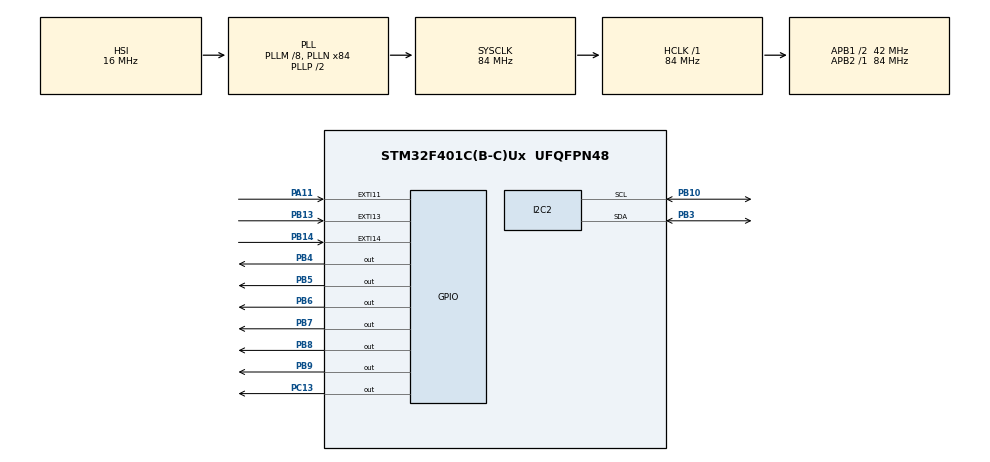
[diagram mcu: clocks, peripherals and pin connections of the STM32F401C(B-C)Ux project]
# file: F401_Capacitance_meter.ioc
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I2C2.I2C_Mode=I2C_Fast
Mcu.Family=STM32F4
Mcu.Name=STM32F401C(B-C)Ux
Mcu.Package=UFQFPN48
NVIC.EXTI15_10_IRQn=true\:0\:0\:false\:false\:true\:true\:true
NVIC.PriorityGroup=NVIC_PRIORITYGROUP_4
NVIC.TIM2_IRQn=true\:0\:0\:false\:false\:true\:true\:true
PA11.Signal=GPXTI11
PA13.Mode=Serial_Wire
PA13.Signal=SYS_JTMS-SWDIO
PA14.Mode=Serial_Wire
PA14.Signal=SYS_JTCK-SWCLK
PB10.Mode=I2C
PB10.Signal=I2C2_SCL
PB13.GPIO_PuPd=GPIO_PULLDOWN
PB13.Signal=GPXTI13
PB14.GPIO_PuPd=GPIO_PULLDOWN
PB14.Signal=GPXTI14
PB3.Mode=I2C
PB3.Signal=I2C2_SDA
PB4.PinState=GPIO_PIN_RESET
PB4.Signal=GPIO_Output
PB5.PinState=GPIO_PIN_SET
PB5.Signal=GPIO_Output
PB6.PinState=GPIO_PIN_SET
PB6.Signal=GPIO_Output
PB7.PinState=GPIO_PIN_SET
PB7.Signal=GPIO_Output
PB8.PinState=GPIO_PIN_SET
PB8.Signal=GPIO_Output
PB9.PinState=GPIO_PIN_SET
PB9.Signal=GPIO_Output
PC13-ANTI_TAMP.PinState=GPIO_PIN_SET
PC13-ANTI_TAMP.Signal=GPIO_Output
PH0\ -\ OSC_IN.Mode=HSE-External-Oscillator
PH0\ -\ OSC_IN.Signal=RCC_OSC_IN
PH1\ -\ OSC_OUT.Mode=HSE-External-Oscillator
PH1\ -\ OSC_OUT.Signal=RCC_OSC_OUT
ProjectManager.HeapSize=0x200
ProjectManager.StackSize=0x400
ProjectManager.TargetToolchain=STM32CubeIDE
RCC.48MHZClocksFreq_Value=42000000
RCC.AHBFreq_Value=84000000
RCC.APB1CLKDivider=RCC_HCLK_DIV2
RCC.APB1Freq_Value=42000000
RCC.APB1TimFreq_Value=84000000
RCC.APB2Freq_Value=84000000
RCC.APB2TimFreq_Value=84000000
RCC.CortexFreq_Value=84000000
RCC.HCLKFreq_Value=84000000
RCC.HSE_VALUE=25000000
RCC.HSI_VALUE=16000000
RCC.LSE_VALUE=32768
RCC.PLLM=8
RCC.PLLN=84
RCC.SYSCLKFreq_VALUE=84000000
RCC.SYSCLKSource=RCC_SYSCLKSOURCE_PLLCLK
RCC.VCOOutputFreq_Value=168000000
TIM2.ClockDivision=TIM_CLOCKDIVISION_DIV1
TIM2.Period=64999
TIM2.Prescaler=0
VP_TIM2_VS_ClockSourceINT.Mode=Internal
board=custom

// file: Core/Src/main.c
/* USER CODE BEGIN Header */
/**
  ******************************************************************************
  * @file           : main.c
  * @brief          : Main program body
  ******************************************************************************
  * @attention
  *
  * <h2><center>&copy; Copyright (c) 2020 STMicroelectronics.
  * All rights reserved.</center></h2>
  *
  * This software component is licensed by ST under BSD 3-Clause license,
  * the "License"; You may not use this file except in compliance with the
  * License. You may obtain a copy of the License at:
  *                        opensource.org/licenses/BSD-3-Clause
  *
  ******************************************************************************
  */
/* USER CODE END Header */

#include "main.h"

/* USER CODE BEGIN Includes */
#include "capacitance_meter.h"
/* USER CODE END Includes */

I2C_HandleTypeDef hi2c2;

TIM_HandleTypeDef htim2;

void SystemClock_Config(void);
static void MX_GPIO_Init(void);
static void MX_I2C2_Init(void);
static void MX_TIM2_Init(void);

int main(void)
{

  /* MCU Configuration--------------------------------------------------------*/

  /* Reset of all peripherals, Initializes the Flash interface and the Systick. */
  HAL_Init();

  /* Configure the system clock */
  SystemClock_Config();

  /* Initialize all configured peripherals */
  MX_GPIO_Init();
  MX_I2C2_Init();
  MX_TIM2_Init();
  /* USER CODE BEGIN 2 */
  main_s();
  /* USER CODE END 2 */

  /* Infinite loop */
  while (1)
  {

  }
}

void SystemClock_Config(void)
{
  RCC_OscInitTypeDef RCC_OscInitStruct = {0};
  RCC_ClkInitTypeDef RCC_ClkInitStruct = {0};

  /** Configure the main internal regulator output voltage
  */
  __HAL_RCC_PWR_CLK_ENABLE();
  __HAL_PWR_VOLTAGESCALING_CONFIG(PWR_REGULATOR_VOLTAGE_SCALE2);
  /** Initializes the CPU, AHB and APB busses clocks
  */
  RCC_OscInitStruct.OscillatorType = RCC_OSCILLATORTYPE_HSI;
  RCC_OscInitStruct.HSIState = RCC_HSI_ON;
  RCC_OscInitStruct.HSICalibrationValue = RCC_HSICALIBRATION_DEFAULT;
  RCC_OscInitStruct.PLL.PLLState = RCC_PLL_ON;
  RCC_OscInitStruct.PLL.PLLSource = RCC_PLLSOURCE_HSI;
  RCC_OscInitStruct.PLL.PLLM = 8;
  RCC_OscInitStruct.PLL.PLLN = 84;
  RCC_OscInitStruct.PLL.PLLP = RCC_PLLP_DIV2;
  RCC_OscInitStruct.PLL.PLLQ = 4;
  if (HAL_RCC_OscConfig(&RCC_OscInitStruct) != HAL_OK)
  {
    Error_Handler();
  }
  /** Initializes the CPU, AHB and APB busses clocks
  */
  RCC_ClkInitStruct.ClockType = RCC_CLOCKTYPE_HCLK|RCC_CLOCKTYPE_SYSCLK
                              |RCC_CLOCKTYPE_PCLK1|RCC_CLOCKTYPE_PCLK2;
  RCC_ClkInitStruct.SYSCLKSource = RCC_SYSCLKSOURCE_PLLCLK;
  RCC_ClkInitStruct.AHBCLKDivider = RCC_SYSCLK_DIV1;
  RCC_ClkInitStruct.APB1CLKDivider = RCC_HCLK_DIV2;
  RCC_ClkInitStruct.APB2CLKDivider = RCC_HCLK_DIV1;

  if (HAL_RCC_ClockConfig(&RCC_ClkInitStruct, FLASH_LATENCY_2) != HAL_OK)
  {
    Error_Handler();
  }
}

static void MX_I2C2_Init(void)
{

  hi2c2.Instance = I2C2;
  hi2c2.Init.ClockSpeed = 400000;
  hi2c2.Init.DutyCycle = I2C_DUTYCYCLE_2;
  hi2c2.Init.OwnAddress1 = 0;
  hi2c2.Init.AddressingMode = I2C_ADDRESSINGMODE_7BIT;
  hi2c2.Init.DualAddressMode = I2C_DUALADDRESS_DISABLE;
  hi2c2.Init.OwnAddress2 = 0;
  hi2c2.Init.GeneralCallMode = I2C_GENERALCALL_DISABLE;
  hi2c2.Init.NoStretchMode = I2C_NOSTRETCH_DISABLE;
  if (HAL_I2C_Init(&hi2c2) != HAL_OK)
  {
    Error_Handler();
  }

}

static void MX_TIM2_Init(void)
{

  TIM_ClockConfigTypeDef sClockSourceConfig = {0};
  TIM_MasterConfigTypeDef sMasterConfig = {0};

  htim2.Instance = TIM2;
  htim2.Init.Prescaler = 0;
  htim2.Init.CounterMode = TIM_COUNTERMODE_UP;
  htim2.Init.Period = 64999;
  htim2.Init.ClockDivision = TIM_CLOCKDIVISION_DIV1;
  htim2.Init.AutoReloadPreload = TIM_AUTORELOAD_PRELOAD_DISABLE;
  if (HAL_TIM_Base_Init(&htim2) != HAL_OK)
  {
    Error_Handler();
  }
  sClockSourceConfig.ClockSource = TIM_CLOCKSOURCE_INTERNAL;
  if (HAL_TIM_ConfigClockSource(&htim2, &sClockSourceConfig) != HAL_OK)
  {
    Error_Handler();
  }
  sMasterConfig.MasterOutputTrigger = TIM_TRGO_RESET;
  sMasterConfig.MasterSlaveMode = TIM_MASTERSLAVEMODE_DISABLE;
  if (HAL_TIMEx_MasterConfigSynchronization(&htim2, &sMasterConfig) != HAL_OK)
  {
    Error_Handler();
  }

}

static void MX_GPIO_Init(void)
{
  GPIO_InitTypeDef GPIO_InitStruct = {0};

  /* GPIO Ports Clock Enable */
  __HAL_RCC_GPIOC_CLK_ENABLE();
  __HAL_RCC_GPIOH_CLK_ENABLE();
  __HAL_RCC_GPIOB_CLK_ENABLE();
  __HAL_RCC_GPIOA_CLK_ENABLE();

  /*Configure GPIO pin Output Level */
  HAL_GPIO_WritePin(GPIOC, GPIO_PIN_13, GPIO_PIN_SET);

  /*Configure GPIO pin Output Level */
  HAL_GPIO_WritePin(GPIOB, GPIO_PIN_4, GPIO_PIN_RESET);

  /*Configure GPIO pin Output Level */
  HAL_GPIO_WritePin(GPIOB, GPIO_PIN_5|GPIO_PIN_6|GPIO_PIN_7|GPIO_PIN_8
                          |GPIO_PIN_9, GPIO_PIN_SET);

  /*Configure GPIO pin : PC13 */
  GPIO_InitStruct.Pin = GPIO_PIN_13;
  GPIO_InitStruct.Mode = GPIO_MODE_OUTPUT_PP;
  GPIO_InitStruct.Pull = GPIO_NOPULL;
  GPIO_InitStruct.Speed = GPIO_SPEED_FREQ_LOW;
  HAL_GPIO_Init(GPIOC, &GPIO_InitStruct);

  /*Configure GPIO pins : PB13 PB14 */
  GPIO_InitStruct.Pin = GPIO_PIN_13|GPIO_PIN_14;
  GPIO_InitStruct.Mode = GPIO_MODE_IT_RISING;
  GPIO_InitStruct.Pull = GPIO_PULLDOWN;
  HAL_GPIO_Init(GPIOB, &GPIO_InitStruct);

  /*Configure GPIO pin : PA11 */
  GPIO_InitStruct.Pin = GPIO_PIN_11;
  GPIO_InitStruct.Mode = GPIO_MODE_IT_RISING;
  GPIO_InitStruct.Pull = GPIO_NOPULL;
  HAL_GPIO_Init(GPIOA, &GPIO_InitStruct);

  /*Configure GPIO pins : PB4 PB5 PB6 PB7
                           PB8 PB9 */
  GPIO_InitStruct.Pin = GPIO_PIN_4|GPIO_PIN_5|GPIO_PIN_6|GPIO_PIN_7
                          |GPIO_PIN_8|GPIO_PIN_9;
  GPIO_InitStruct.Mode = GPIO_MODE_OUTPUT_PP;
  GPIO_InitStruct.Pull = GPIO_NOPULL;
  GPIO_InitStruct.Speed = GPIO_SPEED_FREQ_LOW;
  HAL_GPIO_Init(GPIOB, &GPIO_InitStruct);

  /* EXTI interrupt init*/
  HAL_NVIC_SetPriority(EXTI15_10_IRQn, 0, 0);
  HAL_NVIC_EnableIRQ(EXTI15_10_IRQn);

}

void Error_Handler(void)
{
}

/************************ (C) COPYRIGHT STMicroelectronics *****END OF FILE****/
